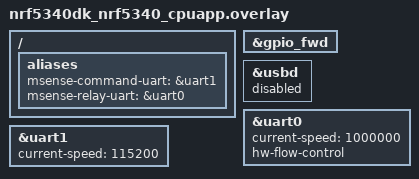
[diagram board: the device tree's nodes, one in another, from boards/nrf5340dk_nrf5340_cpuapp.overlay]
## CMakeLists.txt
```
# SPDX-License-Identifier: Apache-2.0

cmake_minimum_required(VERSION 3.20.0)
find_package(Zephyr REQUIRED HINTS $ENV{ZEPHYR_BASE})
project(central)

target_sources(app PRIVATE
  src/main.c
  src/msense_dfu_wire.c
  src/msense_smp_central.c
  src/msense_dfu_engine.c
  ../shared/ecg_block_format.c
)

include(CTest)
if(BUILD_TESTING)
  find_package(Python3 REQUIRED COMPONENTS Interpreter)
  add_test(
    NAME msense_sensor_stream_geometry
    COMMAND ${CMAKE_COMMAND}
      "-DMSENSE_SOURCE_ROOT=${CMAKE_CURRENT_SOURCE_DIR}/.."
      -P "${CMAKE_CURRENT_SOURCE_DIR}/../shared/tests/cmake/test_sensor_stream_geometry.cmake"
  )
  add_test(
    NAME msense_dfu_host
    COMMAND ${Python3_EXECUTABLE} -m unittest discover
      -s "${CMAKE_CURRENT_SOURCE_DIR}/tests"
      -p "test_msense_dfu.py"
  )
endif()

zephyr_library_include_directories(${ZEPHYR_BASE}/samples/bluetooth)
target_include_directories(app PRIVATE
  ${CMAKE_CURRENT_SOURCE_DIR}/../shared/include
)
```

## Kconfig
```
# SPDX-License-Identifier: Apache-2.0

source "Kconfig.zephyr"

menu "MotionSense Central DFU"

config MSENSE_DFU_REQUIRE_SECURITY
	bool "Require encrypted BLE link for DFU"
	depends on BT_SMP
	default n
	help
	  Reject DFU jobs unless the connected peer has an encrypted BLE link.
	  The v1 default is disabled so existing MotionSense peripherals need no
	  pairing, keys, or host-side signature verification material. A future
	  product policy can enable Bluetooth security and this guard together.

config MSENSE_CENTRAL_NO_PROGRESS_TIMEOUT_MS
	int "Sensor stream receive no-progress timeout (ms)"
	default 15000
	range 1000 60000
	help
	  Disconnect a central v0 receive session that has not accepted a
	  START_ACK or contiguous DATA message within this interval.

endmenu
```

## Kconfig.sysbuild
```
# SPDX-License-Identifier: Apache-2.0

# An nRF5340 Bluetooth host on the application core needs the standard HCI IPC
# controller image on the network core.  These defaults match Nordic's BLE
# Central samples and make the wrapper's merged image runnable on a clean DK.
source "${ZEPHYR_BASE}/share/sysbuild/Kconfig"

config NRF_DEFAULT_IPC_RADIO
	default y

config NETCORE_IPC_RADIO_BT_HCI_IPC
	default y
```

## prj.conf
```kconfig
# Bluetooth LE Central and GATT client
CONFIG_BT=y
CONFIG_CRC=y
CONFIG_BT_CENTRAL=y
CONFIG_BT_GATT_CLIENT=y
CONFIG_BT_NUS_CLIENT=y
CONFIG_BT_GATT_DM=y
CONFIG_BT_DFU_SMP=y
CONFIG_BT_MAX_CONN=1
# GATT Discovery Manager allocates discovery data from the kernel heap.
CONFIG_HEAP_MEM_POOL_SIZE=4096

# Request the same large ATT MTU used by the PPG and ECG firmware. The protocol
# minimum is 128 bytes, but 498 keeps the test transfer reasonably quick.
CONFIG_BT_BUF_ACL_RX_SIZE=502
CONFIG_BT_L2CAP_TX_MTU=498
CONFIG_BT_BUF_ACL_RX_COUNT=16
# A 498-byte ATT write fragments into three 251-byte LL packets. Keep enough
# host and L2CAP buffers for one SMP upload request without starving discovery.
CONFIG_BT_BUF_ACL_TX_SIZE=251
CONFIG_BT_BUF_ACL_TX_COUNT=10
CONFIG_BT_L2CAP_TX_BUF_COUNT=10
CONFIG_BT_ATT_TX_COUNT=8
# Retain automatic link updates while exposing their negotiated results in
# bt_conn callbacks for the throughput report.
CONFIG_BT_DATA_LEN_UPDATE=y
CONFIG_BT_USER_DATA_LEN_UPDATE=y
CONFIG_BT_AUTO_DATA_LEN_UPDATE=y
CONFIG_BT_PHY_UPDATE=y
CONFIG_BT_USER_PHY_UPDATE=y
CONFIG_BT_AUTO_PHY_UPDATE=y

# Two application-owned UARTEs connected to the DK interface MCU.
# The relay uses the asynchronous API; the command port needs RX interrupts.
CONFIG_SERIAL=y
CONFIG_UART_INTERRUPT_DRIVEN=y
CONFIG_UART_ASYNC_API=y

# Keep the VCOM ports deterministic: this tester writes its own text control
# protocol and binary relay, so no console or logging backend owns either port.
CONFIG_CONSOLE=y
CONFIG_UART_CONSOLE=n
CONFIG_STDOUT_CONSOLE=n
CONFIG_RTT_CONSOLE=y
CONFIG_USE_SEGGER_RTT=y
CONFIG_PRINTK=y

# Keep RTT as the only diagnostics/logging backend so neither VCOM port is
# claimed by console or logging output.
CONFIG_LOG=y
CONFIG_LOG_BACKEND_RTT=y
CONFIG_LOG_BACKEND_UART=n
CONFIG_LOG_MODE_DEFERRED=y
CONFIG_LOG_BUFFER_SIZE=8192

CONFIG_MAIN_STACK_SIZE=2048
CONFIG_SYSTEM_WORKQUEUE_STACK_SIZE=2048
CONFIG_HW_STACK_PROTECTION=y

# DFU parsing and MCUmgr CBOR encoding run on the dedicated DFU thread. BLE
# link authentication remains intentionally optional; no pairing or keys are
# required by the default v1 configuration.
CONFIG_ZCBOR=y
CONFIG_ZCBOR_STOP_ON_ERROR=y
```

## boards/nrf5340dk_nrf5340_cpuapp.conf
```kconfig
# UARTE0 is the nRF5340 binary relay and must use async TX. UARTE1 remains
# interrupt-driven for line-oriented VCOM0 command reception.
CONFIG_UART_0_INTERRUPT_DRIVEN=n
CONFIG_UART_0_ASYNC=y
```

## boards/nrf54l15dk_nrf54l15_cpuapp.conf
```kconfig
# The nRF54L15 DK does not support the UARTE0 nrfx driver instance. This
# matches Nordic's central_uart configuration for this board target.
CONFIG_NRFX_UARTE0=n

# The nRF54L15 controller runs with the application image. Keep its HCI ACL
# TX buffers and data-length capability aligned with the 251-byte DLE target.
CONFIG_BT_BUF_ACL_TX_SIZE=251
CONFIG_BT_CTLR_DATA_LENGTH_MAX=251
CONFIG_BT_RX_STACK_SIZE=1200

# UARTE20 is the VCOM1 binary relay and must use async TX. UARTE30 remains
# interrupt-driven for line-oriented VCOM0 command reception.
CONFIG_UART_20_INTERRUPT_DRIVEN=n
CONFIG_UART_20_ASYNC=y
```

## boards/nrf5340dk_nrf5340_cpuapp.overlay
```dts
/*
 * Copyright (c) 2026 The Ohio State University SENSE Lab
 *
 * SPDX-License-Identifier: Apache-2.0
 */

/ {
	aliases {
		msense-command-uart = &uart1;
		msense-relay-uart = &uart0;
	};
};

/*
 * The DK normally forwards the Serial Port 0 pins to the network core when a
 * Bluetooth controller child image is present. This application owns those
 * pins for UARTE1 command/control instead.
 */
&gpio_fwd {
	/delete-node/ uart;
};

/* The tester does not use the DK's native USB peripheral. */
&usbd {
	status = "disabled";
};

/* Serial Port 1/VCOM2: binary relay, with RTS/CTS to pace bursts. */
&uart0 {
	status = "okay";
	current-speed = <1000000>;
	hw-flow-control;
};

/* Serial Port 0/VCOM0: line-oriented command/control, no flow control. */
&uart1 {
	status = "okay";
	current-speed = <115200>;
};
```

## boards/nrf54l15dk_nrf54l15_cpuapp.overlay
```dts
/*
 * Copyright (c) 2026 The Ohio State University SENSE Lab
 *
 * SPDX-License-Identifier: Apache-2.0
 */

/ {
	aliases {
		msense-command-uart = &uart30;
		msense-relay-uart = &uart20;
	};
};

/* Serial Port 0: line-oriented command/control, no flow control. */
&uart30 {
	status = "okay";
	current-speed = <115200>;
};

/* Serial Port 1: binary relay, without hardware flow control. */
&uart20 {
	status = "okay";
	current-speed = <1000000>;
};
```

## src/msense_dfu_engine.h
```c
/*
 * Copyright (c) 2026 The Ohio State University SENSE Lab
 *
 * SPDX-License-Identifier: Apache-2.0
 */

#ifndef MSENSE_DFU_ENGINE_H_
#define MSENSE_DFU_ENGINE_H_

#include <stdbool.h>
#include <stddef.h>
#include <stdint.h>

#include "msense_dfu_wire.h"

#ifdef __cplusplus
extern "C" {
#endif

enum msense_dfu_state {
	MSENSE_DFU_IDLE,
	MSENSE_DFU_LISTING,
	MSENSE_DFU_PREPARING,
	MSENSE_DFU_RECEIVING,
	MSENSE_DFU_VERIFYING,
	MSENSE_DFU_TESTING,
	MSENSE_DFU_RESETTING,
	MSENSE_DFU_RECONNECTING,
	MSENSE_DFU_CONFIRMING,
	MSENSE_DFU_COMPLETE,
	MSENSE_DFU_FAILED,
	MSENSE_DFU_ABORTED,
};

struct msense_dfu_status {
	enum msense_dfu_state state;
	uint32_t transaction;
	uint32_t offset;
	uint32_t image_size;
	uint16_t credit_payload_max;
	uint32_t dropped_frames;
	bool binary_port_claimed;
};

struct msense_dfu_platform {
	int (*claim_binary_port)(void *context);
	void (*release_binary_port)(void *context);
	bool (*smp_ready)(void *context);
	bool (*security_ok)(void *context);
	uint16_t (*att_mtu)(void *context);
	bool (*peer_requires_nus)(void *context);
	void (*request_reconnect)(void *context);
	void (*set_reconnect_enabled)(void *context, bool enabled);
	void *context;
};

typedef void (*msense_dfu_event_cb)(const char *text, void *context);

int msense_dfu_engine_init(const struct msense_dfu_platform *platform,
			   msense_dfu_event_cb event_cb, void *event_context);

int msense_dfu_engine_request_list(uint32_t transaction);
int msense_dfu_engine_request_begin(uint32_t transaction, uint32_t image_size,
				    const uint8_t upload_hash[32],
				    const uint8_t tlv_hash[32], bool allow_same);
int msense_dfu_engine_request_erase(uint32_t transaction, uint32_t slot);
int msense_dfu_engine_request_confirm(uint32_t transaction, const uint8_t hash[32]);
int msense_dfu_engine_request_test(uint32_t transaction, const uint8_t hash[32]);
int msense_dfu_engine_request_reset(uint32_t transaction);
int msense_dfu_engine_abort(uint32_t transaction);

void msense_dfu_engine_receive_frame(const struct msense_dfu_frame *frame);
void msense_dfu_engine_note_wire_error(enum msense_dfu_wire_error error);
void msense_dfu_engine_binary_rx_stopped(void);
void msense_dfu_engine_connection_lost(void);
void msense_dfu_engine_peer_ready(bool nus_ready, bool smp_ready);
void msense_dfu_engine_get_status(struct msense_dfu_status *status);
const char *msense_dfu_engine_state_name(enum msense_dfu_state state);

#ifdef __cplusplus
}
#endif

#endif /* MSENSE_DFU_ENGINE_H_ */
```

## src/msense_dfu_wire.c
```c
/*
 * Copyright (c) 2026 The Ohio State University SENSE Lab
 *
 * SPDX-License-Identifier: Apache-2.0
 */

#include <zephyr/sys/byteorder.h>

#include <stdbool.h>
#include <string.h>

#include "msense_dfu_wire.h"

static const uint8_t mdfu_magic[] = { 'M', 'D', 'F', 'U' };

static uint32_t crc32_update(uint32_t crc, const uint8_t *data, size_t length)
{
	size_t index;

	for (index = 0U; index < length; index++) {
		uint8_t bit;

		crc ^= data[index];
		for (bit = 0U; bit < 8U; bit++) {
			crc = (crc >> 1) ^ ((crc & 1U) ? 0xedb88320U : 0U);
		}
	}

	return crc;
}

uint32_t msense_dfu_wire_crc32(const uint8_t *data, size_t length)
{
	return crc32_update(UINT32_MAX, data, length) ^ UINT32_MAX;
}

static uint32_t frame_crc32(const uint8_t *frame, uint16_t payload_length)
{
	uint32_t crc;

	crc = crc32_update(UINT32_MAX, &frame[4], 16U);
	crc = crc32_update(crc, &frame[MSENSE_DFU_WIRE_HEADER_BYTES], payload_length);
	return crc ^ UINT32_MAX;
}

static void parser_drop_prefix(struct msense_dfu_wire_parser *parser, size_t count)
{
	if (count >= parser->used) {
		parser->used = 0U;
		return;
	}

	memmove(parser->buffer, &parser->buffer[count], parser->used - count);
	parser->used -= count;
}

static bool parser_process_one(struct msense_dfu_wire_parser *parser,
			       msense_dfu_wire_frame_cb frame_cb,
			       msense_dfu_wire_error_cb error_cb, void *context)
{
	uint16_t header_size;
	uint16_t payload_length;
	uint16_t reserved;
	uint32_t received_crc;
	size_t frame_length;

	if (parser->used < sizeof(mdfu_magic)) {
		return false;
	}
	if (memcmp(parser->buffer, mdfu_magic, sizeof(mdfu_magic)) != 0) {
		parser_drop_prefix(parser, 1U);
		return true;
	}
	if (parser->used < MSENSE_DFU_WIRE_HEADER_BYTES) {
		return false;
	}

	header_size = sys_get_le16(&parser->buffer[6]);
	payload_length = sys_get_le16(&parser->buffer[16]);
	reserved = sys_get_le16(&parser->buffer[18]);
	if (parser->buffer[4] != MSENSE_DFU_WIRE_VERSION ||
	    parser->buffer[5] != MSENSE_DFU_WIRE_TYPE_DATA ||
	    header_size != MSENSE_DFU_WIRE_HEADER_BYTES ||
	    payload_length > MSENSE_DFU_WIRE_MAX_PAYLOAD || reserved != 0U) {
		if (error_cb != NULL) {
			error_cb(MSENSE_DFU_WIRE_ERROR_HEADER, context);
		}
		parser_drop_prefix(parser, 1U);
		return true;
	}

	frame_length = MSENSE_DFU_WIRE_HEADER_BYTES + payload_length;
	if (parser->used < frame_length) {
		return false;
	}

	received_crc = sys_get_le32(&parser->buffer[20]);
	if (received_crc != frame_crc32(parser->buffer, payload_length)) {
		if (error_cb != NULL) {
			error_cb(MSENSE_DFU_WIRE_ERROR_CRC, context);
		}
		parser_drop_prefix(parser, 1U);
		return true;
	}

	parser->frame.transaction = sys_get_le32(&parser->buffer[8]);
	parser->frame.offset = sys_get_le32(&parser->buffer[12]);
	parser->frame.payload_length = payload_length;
	memcpy(parser->frame.payload, &parser->buffer[MSENSE_DFU_WIRE_HEADER_BYTES],
	       payload_length);
	if (frame_cb != NULL) {
		frame_cb(&parser->frame, context);
	}
	parser_drop_prefix(parser, frame_length);
	return true;
}

void msense_dfu_wire_parser_init(struct msense_dfu_wire_parser *parser)
{
	memset(parser, 0, sizeof(*parser));
}

void msense_dfu_wire_parser_feed(struct msense_dfu_wire_parser *parser,
				 const uint8_t *data, size_t length,
				 msense_dfu_wire_frame_cb frame_cb,
				 msense_dfu_wire_error_cb error_cb, void *context)
{
	size_t index;

	for (index = 0U; index < length; index++) {
		if (parser->used == sizeof(parser->buffer)) {
			if (error_cb != NULL) {
				error_cb(MSENSE_DFU_WIRE_ERROR_HEADER, context);
			}
			parser_drop_prefix(parser, 1U);
		}
		parser->buffer[parser->used++] = data[index];
		while (parser_process_one(parser, frame_cb, error_cb, context)) {
			/* Consume every complete or invalid frame before accepting more input. */
		}
	}
}
```

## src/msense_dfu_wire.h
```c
/*
 * Copyright (c) 2026 The Ohio State University SENSE Lab
 *
 * SPDX-License-Identifier: Apache-2.0
 */

#ifndef MSENSE_DFU_WIRE_H_
#define MSENSE_DFU_WIRE_H_

#include <stddef.h>
#include <stdint.h>

#ifdef __cplusplus
extern "C" {
#endif

#define MSENSE_DFU_WIRE_VERSION 1U
#define MSENSE_DFU_WIRE_TYPE_DATA 1U
#define MSENSE_DFU_WIRE_HEADER_BYTES 24U
#define MSENSE_DFU_WIRE_MAX_PAYLOAD 384U
#define MSENSE_DFU_WIRE_MAX_FRAME_BYTES \
	(MSENSE_DFU_WIRE_HEADER_BYTES + MSENSE_DFU_WIRE_MAX_PAYLOAD)

enum msense_dfu_wire_error {
	MSENSE_DFU_WIRE_ERROR_HEADER,
	MSENSE_DFU_WIRE_ERROR_CRC,
};

struct msense_dfu_frame {
	uint32_t transaction;
	uint32_t offset;
	uint16_t payload_length;
	uint8_t payload[MSENSE_DFU_WIRE_MAX_PAYLOAD];
};

typedef void (*msense_dfu_wire_frame_cb)(const struct msense_dfu_frame *frame,
					 void *context);
typedef void (*msense_dfu_wire_error_cb)(enum msense_dfu_wire_error error,
					 void *context);

struct msense_dfu_wire_parser {
	uint8_t buffer[MSENSE_DFU_WIRE_MAX_FRAME_BYTES];
	size_t used;
	struct msense_dfu_frame frame;
};

uint32_t msense_dfu_wire_crc32(const uint8_t *data, size_t length);

void msense_dfu_wire_parser_init(struct msense_dfu_wire_parser *parser);

void msense_dfu_wire_parser_feed(struct msense_dfu_wire_parser *parser,
				 const uint8_t *data, size_t length,
				 msense_dfu_wire_frame_cb frame_cb,
				 msense_dfu_wire_error_cb error_cb, void *context);

#ifdef __cplusplus
}
#endif

#endif /* MSENSE_DFU_WIRE_H_ */
```

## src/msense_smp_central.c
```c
/*
 * Copyright (c) 2026 The Ohio State University SENSE Lab
 *
 * SPDX-License-Identifier: Apache-2.0
 */

#include <zephyr/bluetooth/conn.h>
#include <zephyr/kernel.h>
#include <zephyr/sys/atomic.h>

#include <bluetooth/gatt_dm.h>
#include <bluetooth/services/dfu_smp.h>

#include <errno.h>
#include <string.h>

#include "msense_smp_central.h"

#define MSENSE_SMP_RESPONSE_STORAGE_BYTES 2048U

struct smp_central_context {
	struct bt_dfu_smp dfu_smp;
	struct k_mutex command_lock;
	struct k_sem command_complete;
	struct k_work completion_work;
	msense_smp_ready_cb ready_cb;
	void *ready_context;
	uint8_t response_storage[MSENSE_SMP_RESPONSE_STORAGE_BYTES];
	size_t response_length;
	int command_error;
	atomic_t ready;
	atomic_t command_pending;
	atomic_t completion_pending;
	atomic_t transport_stalled;
};

static struct smp_central_context smp_central;

static void smp_error(struct bt_dfu_smp *dfu_smp, int error);

static int reset_dfu_smp_client(void)
{
	const struct bt_dfu_smp_init_params params = {
		.error_cb = smp_error,
	};

	return bt_dfu_smp_init(&smp_central.dfu_smp, &params);
}

static void command_complete_work(struct k_work *work)
{
	ARG_UNUSED(work);
	atomic_set(&smp_central.completion_pending, 0);
	k_sem_give(&smp_central.command_complete);
}

static void schedule_command_completion(void)
{
	if (atomic_cas(&smp_central.completion_pending, 0, 1)) {
		(void)k_work_submit(&smp_central.completion_work);
	}
}

static void smp_error(struct bt_dfu_smp *dfu_smp, int error)
{
	ARG_UNUSED(dfu_smp);
	if (atomic_cas(&smp_central.command_pending, 1, 0)) {
		smp_central.command_error = error;
		schedule_command_completion();
	}
}

static void smp_response_part(struct bt_dfu_smp *dfu_smp)
{
	const struct bt_dfu_smp_rsp_state *state;

	state = bt_dfu_smp_rsp_state(dfu_smp);
	if (!atomic_get(&smp_central.command_pending)) {
		return;
	}
	if (state->offset > sizeof(smp_central.response_storage) ||
	    state->chunk_size > sizeof(smp_central.response_storage) - state->offset) {
		smp_central.command_error = -EMSGSIZE;
	} else {
		memcpy(&smp_central.response_storage[state->offset], state->data, state->chunk_size);
		if (state->offset + state->chunk_size >= state->total_size) {
			smp_central.response_length = state->total_size;
		}
	}

	if (bt_dfu_smp_rsp_total_check(dfu_smp)) {
		if (atomic_cas(&smp_central.command_pending, 1, 0)) {
			schedule_command_completion();
		}
	}
}

static void smp_discovery_complete(struct bt_gatt_dm *dm, void *context)
{
	int error;

	ARG_UNUSED(context);
	error = bt_dfu_smp_handles_assign(dm, &smp_central.dfu_smp);
	(void)bt_gatt_dm_data_release(dm);
	if (error == 0) {
		atomic_set(&smp_central.ready, 1);
	}
	if (smp_central.ready_cb != NULL) {
		smp_central.ready_cb(error == 0, error, smp_central.ready_context);
	}
}

static void smp_discovery_not_found(struct bt_conn *connection, void *context)
{
	ARG_UNUSED(connection);
	ARG_UNUSED(context);
	atomic_set(&smp_central.ready, 0);
	if (smp_central.ready_cb != NULL) {
		smp_central.ready_cb(false, -ENOENT, smp_central.ready_context);
	}
}

static void smp_discovery_error(struct bt_conn *connection, int error, void *context)
{
	ARG_UNUSED(connection);
	ARG_UNUSED(context);
	atomic_set(&smp_central.ready, 0);
	if (smp_central.ready_cb != NULL) {
		smp_central.ready_cb(false, error, smp_central.ready_context);
	}
}

static const struct bt_gatt_dm_cb smp_discovery_callbacks = {
	.completed = smp_discovery_complete,
	.service_not_found = smp_discovery_not_found,
	.error_found = smp_discovery_error,
};

int msense_smp_central_init(msense_smp_ready_cb ready_cb, void *context)
{
	memset(&smp_central, 0, sizeof(smp_central));
	k_mutex_init(&smp_central.command_lock);
	k_sem_init(&smp_central.command_complete, 0, 1);
	k_work_init(&smp_central.completion_work, command_complete_work);
	smp_central.ready_cb = ready_cb;
	smp_central.ready_context = context;
	return reset_dfu_smp_client();
}

int msense_smp_central_discover(struct bt_conn *connection)
{
	int error;

	if (connection == NULL) {
		return -EINVAL;
	}
	atomic_set(&smp_central.ready, 0);
	error = bt_gatt_dm_start(connection, BT_UUID_DFU_SMP_SERVICE,
				&smp_discovery_callbacks, NULL);
	return error;
}

void msense_smp_central_disconnected(struct bt_conn *connection)
{
	ARG_UNUSED(connection);
	atomic_set(&smp_central.ready, 0);
	if (atomic_cas(&smp_central.command_pending, 1, 0)) {
		smp_central.command_error = -ENOTCONN;
		schedule_command_completion();
	}
	/* bt_dfu_smp retains the old connection and volatile subscription object.
	 * Reinitializing at disconnect makes a post-reset rediscovery subscribe to
	 * the new peer instead of trying to use stale notification state. */
	(void)reset_dfu_smp_client();
	atomic_set(&smp_central.transport_stalled, 0);
}

bool msense_smp_central_ready(void)
{
	return atomic_get(&smp_central.ready) != 0;
}

int msense_smp_central_command(const uint8_t *command, size_t command_length,
			       uint8_t *response, size_t response_capacity,
			       size_t *response_length, k_timeout_t timeout)
{
	int error;

	if (command == NULL || command_length == 0U || response == NULL ||
	    response_capacity < sizeof(struct bt_dfu_smp_header) || response_length == NULL) {
		return -EINVAL;
	}
	if (!msense_smp_central_ready()) {
		return -ENOTCONN;
	}
	if (atomic_get(&smp_central.transport_stalled)) {
		return -ETIMEDOUT;
	}

	k_mutex_lock(&smp_central.command_lock, K_FOREVER);
	if (!msense_smp_central_ready()) {
		k_mutex_unlock(&smp_central.command_lock);
		return -ENOTCONN;
	}
	if (atomic_get(&smp_central.transport_stalled)) {
		k_mutex_unlock(&smp_central.command_lock);
		return -ETIMEDOUT;
	}
	k_sem_reset(&smp_central.command_complete);
	smp_central.response_length = 0U;
	smp_central.command_error = 0;
	atomic_set(&smp_central.command_pending, 1);
	error = bt_dfu_smp_command(&smp_central.dfu_smp, smp_response_part,
				   command_length, command);
	if (error != 0) {
		atomic_set(&smp_central.command_pending, 0);
		k_mutex_unlock(&smp_central.command_lock);
		return error;
	}
	if (k_sem_take(&smp_central.command_complete, timeout) != 0) {
		/* The Nordic client intentionally exposes no cancel API. Do not issue a
		 * second request while it can still own its response callback. A new
		 * discovery after disconnect resets this condition. */
		atomic_set(&smp_central.transport_stalled, 1);
		k_mutex_unlock(&smp_central.command_lock);
		return -ETIMEDOUT;
	}
	error = smp_central.command_error;
	if (smp_central.response_length > response_capacity) {
		error = -EMSGSIZE;
	} else if (error == 0) {
		memcpy(response, smp_central.response_storage, smp_central.response_length);
	}
	*response_length = smp_central.response_length;
	k_mutex_unlock(&smp_central.command_lock);
	return error;
}
```

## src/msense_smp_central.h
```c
/*
 * Copyright (c) 2026 The Ohio State University SENSE Lab
 *
 * SPDX-License-Identifier: Apache-2.0
 */

#ifndef MSENSE_SMP_CENTRAL_H_
#define MSENSE_SMP_CENTRAL_H_

#include <stdbool.h>
#include <stddef.h>
#include <stdint.h>

#include <zephyr/kernel.h>

struct bt_conn;

#ifdef __cplusplus
extern "C" {
#endif

typedef void (*msense_smp_ready_cb)(bool ready, int error, void *context);

/** Initialize the singleton SMP-over-BLE transport before Bluetooth is enabled. */
int msense_smp_central_init(msense_smp_ready_cb ready_cb, void *context);

/** Start GATT discovery for the DFU SMP service on an established connection. */
int msense_smp_central_discover(struct bt_conn *connection);

/** Tell the transport that its current connection has been removed. */
void msense_smp_central_disconnected(struct bt_conn *connection);

bool msense_smp_central_ready(void);

/**
 * Send one complete SMP request and wait for its complete response.
 *
 * The caller owns the command and response buffers. Only one call may be in
 * flight. This function is intended for the dedicated DFU thread, never a
 * Bluetooth callback or the system workqueue.
 */
int msense_smp_central_command(const uint8_t *command, size_t command_length,
			       uint8_t *response, size_t response_capacity,
			       size_t *response_length, k_timeout_t timeout);

#ifdef __cplusplus
}
#endif

#endif /* MSENSE_SMP_CENTRAL_H_ */
```
